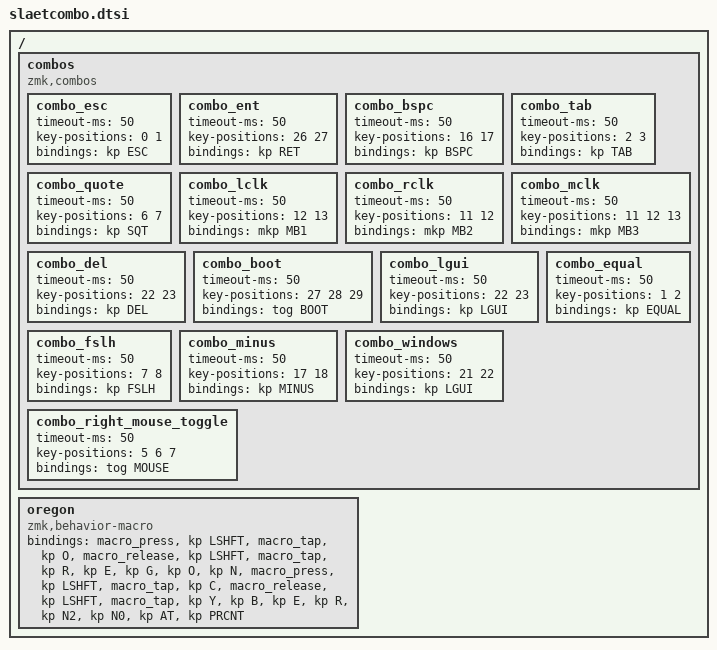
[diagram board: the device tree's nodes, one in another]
/*
  ╭─────────────────────┬─────────────────────╮ 
  │  0   1   2   3   4  │  5   6   7   8   9  │ 
  │ 10  11  12  13  14  │ 15  16  17  18  19  │ 
  │ 20  21  22  23  24  │ 25  26  27  28  29  │ 
  ╰───────╮ 30  31  32  │ 33  34  35 ╭────────╯ 
          ╰─────────────┴────────────╯            */

/ {
    
    combos {
        compatible = "zmk,combos";
        combo_esc {
            timeout-ms = <50>;
            key-positions = <0 1>;
            bindings = <&kp ESC>;
        };
        combo_ent {
            timeout-ms = <50>;
            key-positions = <26 27>;
            bindings = <&kp RET>;
        };
        combo_bspc {
            timeout-ms = <50>;
            key-positions = <16 17>;
            bindings = <&kp BSPC>;
        };
        combo_tab {
            timeout-ms = <50>;
            key-positions = <2 3>;
            bindings = <&kp TAB>;
        };
        combo_quote {
            timeout-ms = <50>;
            key-positions = <6 7>;
            bindings = <&kp SQT>;
        };
        combo_lclk {
            timeout-ms = <50>;
            key-positions = <12 13>;
            bindings = <&mkp MB1>;
        };
        combo_rclk {
            timeout-ms = <50>;
            key-positions = <11 12>;
            bindings = <&mkp MB2>;
        };
        combo_mclk {
            timeout-ms = <50>;
            key-positions = <11 12 13>;
            bindings = <&mkp MB3>;
        };
        combo_del {
            timeout-ms = <50>;
            key-positions = <22 23>;
            bindings = <&kp DEL>;
        };
        combo_boot {
            timeout-ms = <50>;
            key-positions = <27 28 29>;
            bindings = <&tog BOOT>;
        };
        combo_lgui {
            timeout-ms = <50>;
            key-positions = <22 23>;
            bindings = <&kp LGUI>;
        };
        combo_equal {
            timeout-ms = <50>;
            key-positions = <1 2>;
            bindings = <&kp EQUAL>;
        };
        combo_fslh {
            timeout-ms = <50>;
            key-positions = <7 8>;
            bindings = <&kp FSLH>;
        };
            combo_minus {
            timeout-ms = <50>;
            key-positions = <17 18>;
            bindings = <&kp MINUS>;
        };
            combo_windows {
            timeout-ms = <50>;
            key-positions = <21 22>;
            bindings = <&kp LGUI>;
        };           
            combo_right_mouse_toggle {
            timeout-ms = <50>;
            key-positions = <5 6 7>;
            bindings = <&tog MOUSE>;
        };

    };
    oregon: oregon {
        compatible = "zmk,behavior-macro";
        #binding-cells = <0>;
        bindings
            = <&macro_press &kp LSHFT> 
            , <&macro_tap &kp O>
            , <&macro_release &kp LSHFT>
            , <&macro_tap &kp R &kp E &kp G &kp O &kp N>
            , <&macro_press &kp LSHFT> 
            , <&macro_tap &kp C>
            , <&macro_release &kp LSHFT>
            , <&macro_tap &kp Y &kp B &kp E &kp R &kp N2 &kp N0 &kp AT &kp PRCNT>
            ;
        };

};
